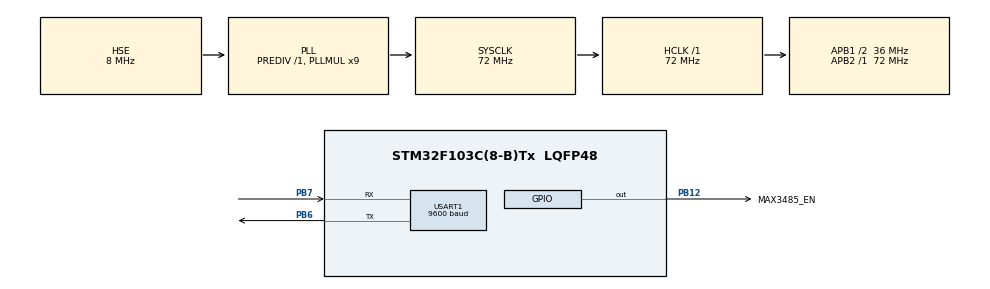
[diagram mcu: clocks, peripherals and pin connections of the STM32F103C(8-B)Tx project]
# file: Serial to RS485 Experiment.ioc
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Mcu.Family=STM32F1
Mcu.Name=STM32F103C(8-B)Tx
Mcu.Package=LQFP48
NVIC.PriorityGroup=NVIC_PRIORITYGROUP_4
NVIC.USART1_IRQn=true\:0\:0\:false\:false\:true\:true\:true\:true
PA13.Mode=Serial_Wire
PA13.Signal=SYS_JTMS-SWDIO
PA14.Mode=Serial_Wire
PA14.Signal=SYS_JTCK-SWCLK
PB12.GPIO_Label=MAX3485_EN
PB12.Signal=GPIO_Output
PB6.Mode=Asynchronous
PB6.Signal=USART1_TX
PB7.Mode=Asynchronous
PB7.Signal=USART1_RX
PD0-OSC_IN.Mode=HSE-External-Oscillator
PD0-OSC_IN.Signal=RCC_OSC_IN
PD1-OSC_OUT.Mode=HSE-External-Oscillator
PD1-OSC_OUT.Signal=RCC_OSC_OUT
ProjectManager.HeapSize=0x200
ProjectManager.StackSize=0x400
ProjectManager.TargetToolchain=MDK-ARM V5.32
RCC.AHBFreq_Value=72000000
RCC.APB1CLKDivider=RCC_HCLK_DIV2
RCC.APB1Freq_Value=36000000
RCC.APB1TimFreq_Value=72000000
RCC.APB2Freq_Value=72000000
RCC.APB2TimFreq_Value=72000000
RCC.HCLKFreq_Value=72000000
RCC.PLLMUL=RCC_PLL_MUL9
RCC.PLLSourceVirtual=RCC_PLLSOURCE_HSE
RCC.SYSCLKFreq_VALUE=72000000
RCC.SYSCLKSource=RCC_SYSCLKSOURCE_PLLCLK
RCC.USBFreq_Value=72000000
USART1.BaudRate=9600
USART1.VirtualMode=VM_ASYNC
board=custom

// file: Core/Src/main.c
/* USER CODE BEGIN Header */
/**
 ******************************************************************************
 * @file           : main.c
 * @brief          : Main program body
 ******************************************************************************
 * @attention
 *
 * Copyright (c) 2026 STMicroelectronics.
 * All rights reserved.
 *
 * This software is licensed under terms that can be found in the LICENSE file
 * in the root directory of this software component.
 * If no LICENSE file comes with this software, it is provided AS-IS.
 *
 ******************************************************************************
 */
/* USER CODE END Header */
#include "main.h"
#include "usart.h"
#include "gpio.h"

/* USER CODE BEGIN PV */
#define RXBUFFER_SIZE 100 // 接收数据缓存区大小 (单位为字节)

uint8_t tx_data[] = "Hello, World!\r\n";

uint8_t rx_buffer[RXBUFFER_SIZE]; // 接收数据缓冲区

/**
 * @brief  串口空闲中断回调函数
 * @param  huart: 串口句柄指针
 * @param  Size: 接收到的数据长度
 * @retval None
 */
void HAL_UARTEx_RxEventCallback(UART_HandleTypeDef *huart, uint16_t Size)
{
  if (huart->Instance == USART1) // 判断是否为USART1的回调
  {
    // 将收到的数据通过USART1发送回去
    // RS485 发送前需要拉高使能引脚 (DE/RE)
    HAL_GPIO_WritePin(MAX3485_EN_GPIO_Port, MAX3485_EN_Pin, GPIO_PIN_SET);

    HAL_UART_Transmit(&huart1, rx_buffer, Size, HAL_MAX_DELAY);

    // 发送完成后需要拉低使能引脚，恢复为接收模式
    HAL_GPIO_WritePin(MAX3485_EN_GPIO_Port, MAX3485_EN_Pin, GPIO_PIN_RESET);

    // 重新开启空闲中断接收
    HAL_UARTEx_ReceiveToIdle_IT(&huart1, rx_buffer, RXBUFFER_SIZE);
  }
}

/* USER CODE END PV */

void SystemClock_Config(void);

int main(void)
{

  /* MCU Configuration--------------------------------------------------------*/

  /* Reset of all peripherals, Initializes the Flash interface and the Systick. */
  HAL_Init();

  /* Configure the system clock */
  SystemClock_Config();

  /* Initialize all configured peripherals */
  MX_GPIO_Init();
  MX_USART1_UART_Init();
  /* USER CODE BEGIN 2 */
  // 开启USART1的空闲中断接收
  HAL_UARTEx_ReceiveToIdle_IT(&huart1, rx_buffer, RXBUFFER_SIZE);

  // 延迟一会并清除状态标志，防止复位瞬间的电平抖动导致串口助手显示乱码 (如 '?')
  HAL_Delay(100);

  /*
     __HAL_UART_CLEAR_FLAG 作用：清除串口的状态标志位。
     UART_FLAG_TC (Transmission Complete) 是发送完成标志。
     在单片机刚上电或复位时，硬件寄存器的初始状态或引脚电平抖动可能触发一个虚假的“发送完成”信号，
     导致串口助手将其误识别为一个杂散字符（即你看到的乱码 '?'）。
     在正式发送数据前手动清除该标志，可以确保发送缓冲区是干净的，从而消除这个乱码。
  */
  __HAL_UART_CLEAR_FLAG(&huart1, UART_FLAG_TC);

  // 初始发送Hello World
  // RS485 发送前需要拉高使能引脚
  HAL_GPIO_WritePin(MAX3485_EN_GPIO_Port, MAX3485_EN_Pin, GPIO_PIN_SET);
  HAL_UART_Transmit(&huart1, tx_data, sizeof(tx_data) - 1, HAL_MAX_DELAY);
  // 发送完成后拉低，进入接收模式
  HAL_GPIO_WritePin(MAX3485_EN_GPIO_Port, MAX3485_EN_Pin, GPIO_PIN_RESET);
  /* USER CODE END 2 */

  /* Infinite loop */
  while (1)
  {

  }
}

void SystemClock_Config(void)
{
  RCC_OscInitTypeDef RCC_OscInitStruct = {0};
  RCC_ClkInitTypeDef RCC_ClkInitStruct = {0};

  /** Initializes the RCC Oscillators according to the specified parameters
  * in the RCC_OscInitTypeDef structure.
  */
  RCC_OscInitStruct.OscillatorType = RCC_OSCILLATORTYPE_HSE;
  RCC_OscInitStruct.HSEState = RCC_HSE_ON;
  RCC_OscInitStruct.HSEPredivValue = RCC_HSE_PREDIV_DIV1;
  RCC_OscInitStruct.HSIState = RCC_HSI_ON;
  RCC_OscInitStruct.PLL.PLLState = RCC_PLL_ON;
  RCC_OscInitStruct.PLL.PLLSource = RCC_PLLSOURCE_HSE;
  RCC_OscInitStruct.PLL.PLLMUL = RCC_PLL_MUL9;
  if (HAL_RCC_OscConfig(&RCC_OscInitStruct) != HAL_OK)
  {
    Error_Handler();
  }

  /** Initializes the CPU, AHB and APB buses clocks
  */
  RCC_ClkInitStruct.ClockType = RCC_CLOCKTYPE_HCLK|RCC_CLOCKTYPE_SYSCLK
                              |RCC_CLOCKTYPE_PCLK1|RCC_CLOCKTYPE_PCLK2;
  RCC_ClkInitStruct.SYSCLKSource = RCC_SYSCLKSOURCE_PLLCLK;
  RCC_ClkInitStruct.AHBCLKDivider = RCC_SYSCLK_DIV1;
  RCC_ClkInitStruct.APB1CLKDivider = RCC_HCLK_DIV2;
  RCC_ClkInitStruct.APB2CLKDivider = RCC_HCLK_DIV1;

  if (HAL_RCC_ClockConfig(&RCC_ClkInitStruct, FLASH_LATENCY_2) != HAL_OK)
  {
    Error_Handler();
  }
}

void Error_Handler(void)
{
  __disable_irq();
  while (1)
  {
  }
}
